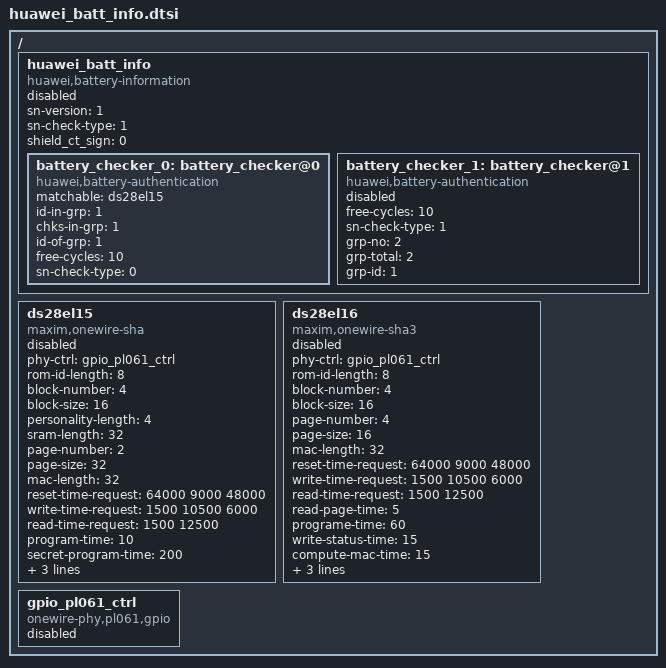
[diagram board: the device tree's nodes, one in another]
/{
	huawei_batt_info: huawei_batt_info {
		#address-cells = <1>;
		#size-cells = <0>;
		compatible = "huawei,battery-information";
		sn-version = <1>;
		sn-check-type = <1>;
		shield_ct_sign = <0>;
		status = "disabled";
		battery_checker_0: battery_checker@0 {
			compatible = "huawei,battery-authentication";
			matchable = <&ds28el15>;
			/* 0 group number, 1 group total checkers number, 0 group id */
			id-in-grp = /bits/ 8 <1>;
			chks-in-grp = /bits/ 8 <1>;
			id-of-grp = /bits/ 8 <1>;
			free-cycles = <10>;
			sn-check-type = <0>; /* 0 always success, 1 normal checking */
			status = "ok";
		};
		battery_checker_1: battery_checker@1 {
			compatible = "huawei,battery-authentication";
			/* matchable = <&ds28el15_1>; */
			free-cycles = <10>;
			sn-check-type = <1>;
			grp-no = /bits/ 8 <2>;
			grp-total = /bits/ 8 <2>;
			grp-id = /bits/ 8 <1>;
			status = "disabled";
		};
	};

	ds28el15: ds28el15 {
		compatible = "maxim,onewire-sha";
		phy-ctrl = <&gpio_pl061_ctrl>;
		rom-id-length = <8>;
		/* id-mask = /bits/ 8 <0x00 0x00 0x00 0x00 0x00 0x00 0x00 0x00>; */
		/* id-example = /bits/ 8 <0x00 0x00 0x00 0x00 0x00 0x00 0x00 0x00>; */
		block-number = <4>;
		block-size = <16>;
		personality-length = <4>;
		sram-length = <32>;
		page-number = <2>;
		page-size = <32>;
		mac-length = <32>;
		reset-time-request = <64000 9000 48000>;
		write-time-request = <1500 10500 6000>;
		read-time-request = <1500 12500>;
		program-time = <10>;
		secret-program-time = <200>;
		compute-mac-time  = <3>;
		sn-page = <1>;
		sn-offset-bits = <8>;
		status = "disabled";
	};

	ds28el16: ds28el16 {
		compatible = "maxim,onewire-sha3";
		phy-ctrl = <&gpio_pl061_ctrl>;
		rom-id-length = <8>;
		/* id-mask = /bits/ 8 <0x00 0x00 0x00 0x00 0x00 0x00 0x00 0x00>; */
		/* id-example = /bits/ 8 <0x00 0x00 0x00 0x00 0x00 0x00 0x00 0x00>; */
		block-number = <4>;
		block-size = <16>;
		page-number = <4>;
		page-size = <16>;
		mac-length = <32>;
		reset-time-request = <64000 9000 48000>;
		write-time-request = <1500 10500 6000>;
		read-time-request = <1500 12500>;
		read-page-time = <5>;
		programe-time = <60>;
		write-status-time = <15>;
		compute-mac-time = <15>;
		sn-page = <1>;
		sn-offset-bits = <8>;
		check-key-page-stauts = <1>;
		status = "disabled";
	};


	gpio_pl061_ctrl: gpio_pl061_ctrl {
		compatible = "onewire-phy,pl061,gpio";
		/* onewire-gpio = <&gpio6 7 0>; */
		status = "disabled";
	};
};
